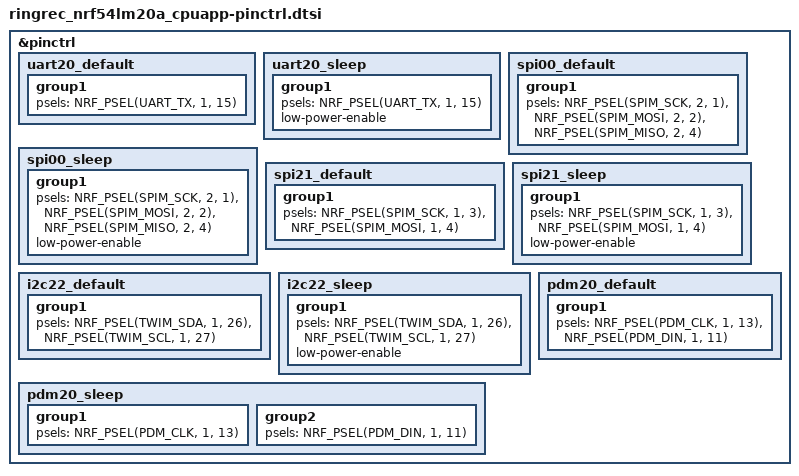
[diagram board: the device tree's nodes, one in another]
/*
 * The ring (software step 7): pin states of the serial, SPI, I2C and PDM peripherals.
 * Source of every pin: design/ecad/ring/netlist.csv, rows of U1 (with design/ecad/ring-route-f/pin-changes.md).
 * The net name of each pin is written beside it; tools/check_ring_pins.py compares the built devicetree with the netlist.
 */

&pinctrl {
	/* debug log, send only: DBG_TX (ball B4). No receive pin on the ring board. */
	uart20_default: uart20_default {
		group1 {
			psels = <NRF_PSEL(UART_TX, 1, 15)>;          /* DBG_TX */
		};
	};

	uart20_sleep: uart20_sleep {
		group1 {
			psels = <NRF_PSEL(UART_TX, 1, 15)>;          /* DBG_TX */
			low-power-enable;
		};
	};

	/* storage card (design/firmware.md 5.1). Default: SCK and MOSI driven (low when idle). Sleep: SD_SCK, SD_MOSI and
	 * SD_MISO inputs with no pull (disconnected), part of the FW 5.1 rule that no line is driven high while VDD_SD is
	 * off (the pull-ups R60, R63 to R65 go to VDD_SD). The fourth line, SD_CS, is a GPIO (cs-gpios of spi00) and in no
	 * pin state: the kit's SPI driver keeps it an output; modules/ring_store/src/rst_hw_real.c disconnects it after each
	 * suspend and at boot and drives it again before each resume (firmware/docs/board-notes.md, fix round 1, S7-02). */
	spi00_default: spi00_default {
		group1 {
			psels = <NRF_PSEL(SPIM_SCK, 2, 1)>,          /* SD_SCK */
				<NRF_PSEL(SPIM_MOSI, 2, 2)>,         /* SD_MOSI */
				<NRF_PSEL(SPIM_MISO, 2, 4)>;         /* SD_MISO */
		};
	};

	spi00_sleep: spi00_sleep {
		group1 {
			psels = <NRF_PSEL(SPIM_SCK, 2, 1)>,          /* SD_SCK */
				<NRF_PSEL(SPIM_MOSI, 2, 2)>,         /* SD_MOSI */
				<NRF_PSEL(SPIM_MISO, 2, 4)>;         /* SD_MISO */
			low-power-enable;
		};
	};

	/* screen bus, write only (no MISO on the panel connector J1) */
	spi21_default: spi21_default {
		group1 {
			psels = <NRF_PSEL(SPIM_SCK, 1, 3)>,          /* LCD_SCK */
				<NRF_PSEL(SPIM_MOSI, 1, 4)>;         /* LCD_MOSI */
		};
	};

	spi21_sleep: spi21_sleep {
		group1 {
			psels = <NRF_PSEL(SPIM_SCK, 1, 3)>,          /* LCD_SCK */
				<NRF_PSEL(SPIM_MOSI, 1, 4)>;         /* LCD_MOSI */
			low-power-enable;
		};
	};

	/* power chip bus; pull-ups R57 (SDA) and R58 (SCL) are on the board, so no internal pull */
	i2c22_default: i2c22_default {
		group1 {
			psels = <NRF_PSEL(TWIM_SDA, 1, 26)>,         /* PMIC_SDA */
				<NRF_PSEL(TWIM_SCL, 1, 27)>;         /* PMIC_SCL */
		};
	};

	i2c22_sleep: i2c22_sleep {
		group1 {
			psels = <NRF_PSEL(TWIM_SDA, 1, 26)>,         /* PMIC_SDA */
				<NRF_PSEL(TWIM_SCL, 1, 27)>;         /* PMIC_SCL */
			low-power-enable;
		};
	};

	/* microphones (design/firmware.md 4.1, 4.5). Default: the clock driven by the PDM, data in. Sleep: the clock is a
	 * plain output held low (no low-power-enable: the kit's pinctrl_nrf.c sets a PDM_CLK pin to output with the
	 * value 0), the data an input with no pull: "MIC_A_CLK is driven low whenever VDD_MIC is off" (FW l.465). */
	pdm20_default: pdm20_default {
		group1 {
			psels = <NRF_PSEL(PDM_CLK, 1, 13)>,          /* MIC_A_CLK */
				<NRF_PSEL(PDM_DIN, 1, 11)>;          /* MIC_A_DATA */
		};
	};

	pdm20_sleep: pdm20_sleep {
		group1 {
			psels = <NRF_PSEL(PDM_CLK, 1, 13)>;          /* MIC_A_CLK */
		};

		group2 {
			psels = <NRF_PSEL(PDM_DIN, 1, 11)>;          /* MIC_A_DATA */
		};
	};
};
